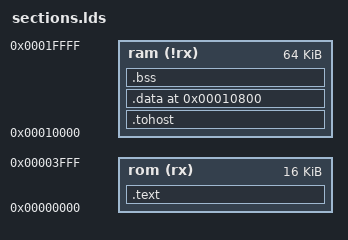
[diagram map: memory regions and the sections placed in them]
/* Two regions. This core is Harvard: imem_addr indexes ROM, mem_addr indexes RAM. */
MEMORY {
    rom(rx)  : ORIGIN = 0x00000000, LENGTH = 16K
    ram(!rx) : ORIGIN = 0x00010000, LENGTH = 64K
}

SECTIONS {
    .text : {
        *(.text.init);
        *(.text);
        . = ALIGN(4);
    } >rom

    .tohost : {
        *(.tohost);
        . = ALIGN(4);
    } >ram

    .data ORIGIN(ram) + 2048 : {
        *(.data);
        *(.rodata);
        *(.rodata.*);
        . = ALIGN(4);
    } >ram

    .bss : {
        *(.bss);
        . = ALIGN(4);
    } >ram

    ASSERT(ADDR(.data) >= ORIGIN(ram) + 2048 &&
           ADDR(.data) < ORIGIN(ram) + LENGTH(ram) - 2048,
           "layout: .data starts in ram's first or last 2 KB block, so every access through a pointer into it pays rtl/decoder.v's one-cycle region wait. Start it one 2 KB block above ORIGIN(ram).")
}
